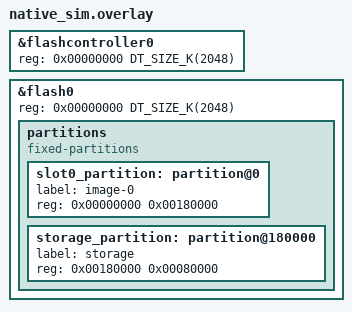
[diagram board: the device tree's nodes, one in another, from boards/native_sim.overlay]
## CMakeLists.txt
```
# SPDX-License-Identifier: GPL-3.0-or-later
#
# Method 4 (PAIRING_CA_ANCHOR) pairing gate conformance on native_sim (T-19).
#
# Drives pairing.c (CA_ANCHOR path) + ca.c + storage.c against a simulated
# LittleFS partition.  A session stub injects client cert chains; ca.c
# (provisioned with a real slot-0 CA) is used to sign test client certs.
#
# Build:
#   ZEPHYR_TOOLCHAIN_VARIANT=host \
#     west build -p -b native_sim firmware/tests/pairing_ca_anchor --no-sysbuild
#   west build -t run

cmake_minimum_required(VERSION 3.20.0)

find_package(Zephyr REQUIRED HINTS $ENV{ZEPHYR_BASE})
project(pairing_ca_anchor_tests LANGUAGES C)

set(FW ${CMAKE_CURRENT_SOURCE_DIR}/../..)

target_sources(app PRIVATE
    src/main.c
    src/session_stub.c
    ${FW}/src/clients/pairing.c
    ${FW}/src/ca/ca.c
    ${FW}/src/ca/der_write.c
    ${FW}/src/ca/certparse_wolfssl.c
    ${FW}/src/ca/certgen_wolfssl.c
    ${FW}/src/crypto/crypto_wolfssl.c
    ${FW}/src/crypto/wc_rand.c
    ${FW}/src/crypto/zeroize.c
    ${FW}/src/storage/storage.c
    ${FW}/src/storage/volume_marker.c
    ${FW}/src/crypto/device_id.c
    ${FW}/../common/cbor/cantil_cbor.c
)

target_include_directories(app PRIVATE
    ${FW}/src
    ${FW}/include
    ${FW}/../common/cbor
    ${FW}/tests/common
)

zephyr_include_directories(${FW}/include)

# Carries WOLFSSL_USER_SETTINGS / WOLFSSL_ZEPHYR defines.
target_link_libraries(app PRIVATE wolfSSL)
```

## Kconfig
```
# SPDX-License-Identifier: GPL-3.0-or-later

mainmenu "pairing_ca_anchor ztest"

config CANTIL_MAX_KEY_SLOTS
	int "Maximum number of key slots"
	default 8
	range 1 64

config CANTIL_CRL_VALIDITY_SEC
	int "CRL nextUpdate window (seconds)"
	default 86400

config CANTIL_REVOKE_REQUIRE_NOW_UNIX
	bool "Require host-supplied revocation timestamp"
	default n

# Pairing method symbols — flat booleans (no choice wrapper in test context).
config PAIRING_PROMISCUOUS
	bool "Method 0 — Promiscuous"
	default n

config PAIRING_TOFU
	bool "Method 1 — Silent TOFU"
	default n

config PAIRING_TAP_CONFIRM
	bool "Method 2 — Tap-confirmed bond"
	default n

config PAIRING_PASSKEY
	bool "Method 3 — Passkey + tap-confirmed bond"
	default n

config PAIRING_CA_ANCHOR
	bool "Method 4 — CA-anchored client cert"
	default n

config CANTIL_CA_ANCHOR_SLOT
	int "CA slot to use as trust anchor for Method 4"
	default 0
	depends on PAIRING_CA_ANCHOR

source "Kconfig.zephyr"
```

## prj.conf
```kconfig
# ztest framework
CONFIG_ZTEST=y

# Pairing method under test.
CONFIG_PAIRING_CA_ANCHOR=y
CONFIG_CANTIL_CA_ANCHOR_SLOT=0
CONFIG_CANTIL_MAX_KEY_SLOTS=8

# Entropy — native_sim has zephyr,native-posix-rng.
CONFIG_ENTROPY_GENERATOR=y
CONFIG_TEST_RANDOM_GENERATOR=y

# LittleFS on the sim flash partition.
CONFIG_FLASH=y
CONFIG_FLASH_MAP=y
CONFIG_FILE_SYSTEM=y
CONFIG_FILE_SYSTEM_LITTLEFS=y
CONFIG_FS_LITTLEFS_FMP_DEV=y
CONFIG_FILE_SYSTEM_MKFS=y

# wolfCrypt — full CA path (ECDSA P-256, AES-256-GCM, HKDF-SHA256) plus the
# X.509 writer and reader. Which primitives compile is decided by the settings
# header, not by Kconfig — see cantil_wolfssl_user_settings.h.
CONFIG_WOLFSSL=y
CONFIG_WOLFSSL_BUILTIN=y
CONFIG_WOLFSSL_SETTINGS_FILE="cantil_wolfssl_user_settings.h"

# Device-id source for the FICR-derived storage key.
CONFIG_HWINFO=y

CONFIG_MAIN_STACK_SIZE=16384
CONFIG_HEAP_MEM_POOL_SIZE=32768

# crc32_ieee — storage.c volume identity marker
CONFIG_CRC=y
```

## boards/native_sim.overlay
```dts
/* Same flash layout as sign_csr / session_slot tests — 512 KB storage partition. */

&flashcontroller0 {
	reg = <0x00000000 DT_SIZE_K(2048)>;
};

&flash0 {
	reg = <0x00000000 DT_SIZE_K(2048)>;
	partitions {
		compatible = "fixed-partitions";
		#address-cells = <1>;
		#size-cells = <1>;

		/delete-node/ partition@0;
		/delete-node/ partition@c000;
		/delete-node/ partition@75000;
		/delete-node/ partition@de000;
		/delete-node/ partition@fc000;

		slot0_partition: partition@0 {
			label = "image-0";
			reg = <0x00000000 0x00180000>;
		};
		storage_partition: partition@180000 {
			label = "storage";
			reg = <0x00180000 0x00080000>;
		};
	};
};
```

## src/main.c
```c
/* SPDX-License-Identifier: GPL-3.0-or-later */
/* See LICENSE at the repo root. */

/*
 * Method 4 (PAIRING_CA_ANCHOR) pairing gate conformance on native_sim (T-19).
 *
 * Drives pairing.c + ca.c + storage.c against a simulated flash partition.
 * Suite setup provisions slot 0 as a CA (the trust anchor) and generates a
 * test client cert signed by it.  Per-test setup resets the session stub.
 *
 * Coverage:
 *   1. Valid client cert (signed by slot 0) → 0 (session allowed, no bond).
 *   2. No client cert in msg3 (cert_count == 0) → -EACCES.
 *   3. Client cert self-signed (not by slot 0) → -EACCES.
 *   4. Slot 0 anchor not provisioned (cert.der deleted) → -EACCES.
 *   5. Corrupted cert DER (random bytes) → -EACCES.
 */

#include <zephyr/kernel.h>
#include <zephyr/ztest.h>
#include <zephyr/fs/fs.h>
#include <string.h>
#include <errno.h>

#include "ca/ca.h"
#include "test_pki.h"
#include "crypto/crypto.h"
#include "storage/storage.h"
#include "clients/pairing.h"
#include "session/session.h"

/* Declared in session_stub.c */
cantil_session_t *ca_anchor_test_session(void);
void ca_anchor_test_set_client_certs(const uint8_t *const ders[], const size_t lens[],
				     size_t count);
void ca_anchor_test_clear_client_certs(void);

/* ── Test-owned cert DER buffers (populated once in suite_setup) ─────────── */

static uint8_t g_anchor_cert_der[1024]; /* slot 0 CA cert — trust anchor */
static size_t g_anchor_cert_len;

static uint8_t g_valid_cert_der[1024]; /* client cert signed by slot 0 */
static size_t g_valid_cert_len;

static uint8_t g_self_signed_cert_der[1024]; /* cert with unknown CA */
static size_t g_self_signed_cert_len;

/* ── Helpers ─────────────────────────────────────────────────────────────── */

static void wipe_dir(const char *path)
{
	struct fs_dir_t dir;
	struct fs_dirent ent;
	char child[128];

	fs_dir_t_init(&dir);
	if (fs_opendir(&dir, path) != 0) {
		return;
	}
	while (fs_readdir(&dir, &ent) == 0 && ent.name[0] != '\0') {
		snprintf(child, sizeof(child), "%s/%s", path, ent.name);
		if (ent.type == FS_DIR_ENTRY_DIR) {
			wipe_dir(child);
		}
		fs_unlink(child);
	}
	fs_closedir(&dir);
	fs_unlink(path);
}

static size_t build_ca_x509_blob(uint8_t *out, size_t cap)
{
	size_t off = 0;
	const char *cn = "Cantil Test CA";
	const char *o = "Cantil";

	zassert_true(cap >= 64, "blob buffer too small");
	out[off++] = 0x01;
	out[off++] = 0x68; /* validity_days = 360 */
	out[off++] = 1;    /* is_ca */
	out[off++] = 0;    /* path_len = 0 */
	out[off++] = 0x00;
	out[off++] = 0x86; /* KU: digSig|keyCertSign|cRLSign */

	out[off++] = (uint8_t)strlen(cn);
	memcpy(&out[off], cn, strlen(cn));
	off += strlen(cn);
	out[off++] = (uint8_t)strlen(o);
	memcpy(&out[off], o, strlen(o));
	off += strlen(o);
	out[off++] = 0; /* ou */
	out[off++] = 0; /* c  */
	out[off++] = 0; /* st */
	out[off++] = 0; /* l  */
	return off;
}

/* A fresh client CSR (CN=TestClient), minted via the wolfCrypt writer. */
static int build_client_csr(uint8_t *csr_der, size_t *csr_len)
{
	return test_pki_csr_cn("TestClient", csr_der, csr_len, NULL);
}

/* A self-signed leaf under an unrelated key (CN=Unknown) — a cert that does
 * NOT chain to slot 0, which the trust-tier tests expect to be rejected. */
static int build_self_signed_cert(uint8_t *cert_der, size_t *cert_len)
{
	certgen_dn_t dn = test_pki_dn_cn("Unknown");

	return test_pki_self_signed(&dn, false, cert_der, cert_len, NULL);
}

/* ── Suite setup ─────────────────────────────────────────────────────────── */

static void *suite_setup(void)
{
	zassert_ok(storage_init(), "storage_init failed");

	/*
	 * A fresh native_sim volume has no identity marker, and minting is now
	 * refused on an unmarked, empty volume — that combination is what a
	 * misdeclared partition looks like. Mark it, which is exactly what the
	 * factory image does to real hardware before anything is provisioned.
	 */
	(void)storage_volume_marker_write();

	/* Provision slot 0 as trust anchor CA. */
	wipe_dir("/lfs/keys/0");
	zassert_ok(ca_provision(0), "ca_provision failed");

	uint8_t blob[64];
	size_t blob_len = build_ca_x509_blob(blob, sizeof(blob));

	zassert_ok(ca_push_key_x509(0, blob, blob_len), "ca_push_key_x509 failed");
	zassert_true(ca_ready(), "slot 0 not ready after push");

	/* Save the anchor cert for test 4's restore path. */
	g_anchor_cert_len = sizeof(g_anchor_cert_der);
	zassert_ok(storage_slot_cert_read(0, g_anchor_cert_der, &g_anchor_cert_len),
		   "could not read slot 0 cert after push");

	/* Sign a test client CSR with slot 0 → g_valid_cert_der. */
	uint8_t csr_buf[512];
	size_t csr_len = sizeof(csr_buf);

	zassert_ok(build_client_csr(csr_buf, &csr_len), "client CSR build failed");

	g_valid_cert_len = sizeof(g_valid_cert_der);
	zassert_ok(ca_sign_csr_slot(0, csr_buf, csr_len, g_valid_cert_der, &g_valid_cert_len),
		   "CA sign CSR failed");

	/* Build a self-signed cert not anchored in slot 0 → g_self_signed_cert_der. */
	g_self_signed_cert_len = sizeof(g_self_signed_cert_der);
	zassert_ok(build_self_signed_cert(g_self_signed_cert_der, &g_self_signed_cert_len),
		   "self-signed cert build failed");

	return NULL;
}

static void before(void *unused)
{
	ARG_UNUSED(unused);
	ca_anchor_test_clear_client_certs();
}

ZTEST_SUITE(pairing_ca_anchor, NULL, suite_setup, before, NULL, NULL);

static const uint8_t PUB_A[32] = {0xAA, 0x01, 0x02, 0x03};

/* ── Test 1: valid cert (signed by slot 0) → allowed ────────────────────── */

ZTEST(pairing_ca_anchor, test_valid_cert_allowed)
{
	const uint8_t *ders[1] = {g_valid_cert_der};
	size_t lens[1] = {g_valid_cert_len};

	ca_anchor_test_set_client_certs(ders, lens, 1);

	cantil_session_t *s = ca_anchor_test_session();

	zassert_ok(pairing_check_and_bond(PUB_A, s), "Method 4: valid cert should be allowed");
}

/* ── Test 2: no cert chain → rejected ───────────────────────────────────── */

ZTEST(pairing_ca_anchor, test_no_cert_rejected)
{
	cantil_session_t *s = ca_anchor_test_session();
	int rc = pairing_check_and_bond(PUB_A, s);

	zassert_equal(rc, -EACCES, "Method 4: no cert should be rejected, got %d", rc);
}

/* ── Test 3: self-signed cert (not from slot 0) → rejected ──────────────── */

ZTEST(pairing_ca_anchor, test_wrong_ca_rejected)
{
	const uint8_t *ders[1] = {g_self_signed_cert_der};
	size_t lens[1] = {g_self_signed_cert_len};

	ca_anchor_test_set_client_certs(ders, lens, 1);

	cantil_session_t *s = ca_anchor_test_session();
	int rc = pairing_check_and_bond(PUB_A, s);

	zassert_equal(rc, -EACCES, "Method 4: cert from wrong CA should be rejected, got %d", rc);
}

/* ── Test 4: slot 0 cert.der deleted (anchor missing) → rejected ─────────── */

ZTEST(pairing_ca_anchor, test_anchor_missing_rejected)
{
	/* Temporarily remove the anchor cert. */
	zassert_ok(fs_unlink("/lfs/keys/0/cert.der"), "could not delete anchor cert for test");

	const uint8_t *ders[1] = {g_valid_cert_der};
	size_t lens[1] = {g_valid_cert_len};

	ca_anchor_test_set_client_certs(ders, lens, 1);

	cantil_session_t *s = ca_anchor_test_session();
	int rc = pairing_check_and_bond(PUB_A, s);

	/* Restore the anchor cert so test 5 can still use it. */
	zassert_ok(storage_slot_cert_write(0, g_anchor_cert_der, g_anchor_cert_len),
		   "restore of anchor cert failed — test 5 may fail");

	zassert_equal(rc, -EACCES, "Method 4: missing anchor should reject, got %d", rc);
}

/* ── Test 5: corrupted cert DER → rejected ───────────────────────────────── */

ZTEST(pairing_ca_anchor, test_corrupted_cert_rejected)
{
	static const uint8_t junk[32] = {
		0xFF, 0xFE, 0xFD, 0xFC, 0xFB, 0xFA, 0xF9, 0xF8, 0xF7, 0xF6, 0xF5,
		0xF4, 0xF3, 0xF2, 0xF1, 0xF0, 0xEF, 0xEE, 0xED, 0xEC, 0xEB, 0xEA,
		0xE9, 0xE8, 0xE7, 0xE6, 0xE5, 0xE4, 0xE3, 0xE2, 0xE1, 0xE0,
	};
	const uint8_t *ders[1] = {junk};
	size_t lens[1] = {sizeof(junk)};

	ca_anchor_test_set_client_certs(ders, lens, 1);

	cantil_session_t *s = ca_anchor_test_session();
	int rc = pairing_check_and_bond(PUB_A, s);

	zassert_equal(rc, -EACCES, "Method 4: corrupted cert should be rejected, got %d", rc);
}
```

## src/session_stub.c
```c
/* SPDX-License-Identifier: GPL-3.0-or-later */
/* See LICENSE at the repo root. */

/*
 * Session stub for the pairing_ca_anchor ztest suite (T-19).
 *
 * pairing.c (PAIRING_CA_ANCHOR) calls:
 *   session_get_client_cert_count() — how many client certs the peer sent
 *   session_get_client_cert()       — borrow the Nth cert DER
 *
 * Test controls (called from main.c):
 *   ca_anchor_test_session()           — return the stub cantil_session_t
 *   ca_anchor_test_set_client_certs()  — inject cert chain for next call
 *   ca_anchor_test_clear_client_certs() — reset to "no cert" (cert_count == 0)
 */

#include <zephyr/kernel.h>
#include <string.h>
#include <errno.h>

#include "session/session.h"

#define MAX_TEST_CERTS 4

/* Minimal concrete struct — opaque in session.h. */
struct cantil_session {
	bool established;
	/* Injected client cert chain (borrowed pointers — not freed here). */
	const uint8_t *cert_ders[MAX_TEST_CERTS];
	size_t cert_lens[MAX_TEST_CERTS];
	size_t cert_count;
};

static struct cantil_session stub_session = {.established = true};

cantil_session_t *ca_anchor_test_session(void)
{
	return &stub_session;
}

void ca_anchor_test_set_client_certs(const uint8_t *const ders[], const size_t lens[], size_t count)
{
	stub_session.cert_count = (count > MAX_TEST_CERTS) ? MAX_TEST_CERTS : count;
	for (size_t i = 0; i < stub_session.cert_count; i++) {
		stub_session.cert_ders[i] = ders[i];
		stub_session.cert_lens[i] = lens[i];
	}
}

void ca_anchor_test_clear_client_certs(void)
{
	stub_session.cert_count = 0;
}

/* ── session API stubs ─────────────────────────────────────────────────── */

size_t session_get_client_cert_count(const cantil_session_t *s)
{
	return s ? s->cert_count : 0;
}

int session_get_client_cert(const cantil_session_t *s, size_t idx, const uint8_t **der, size_t *len)
{
	if (!s || !der || !len) {
		return -EINVAL;
	}
	if (idx >= s->cert_count) {
		return -ENOENT;
	}
	*der = s->cert_ders[idx];
	*len = s->cert_lens[idx];
	return 0;
}

/* Remaining session API is not called by pairing.c (PAIRING_CA_ANCHOR). */

int session_open(cantil_transport_t *t, const uint8_t *pub, cantil_session_t **out)
{
	ARG_UNUSED(t);
	ARG_UNUSED(pub);
	ARG_UNUSED(out);
	return -ENOSYS;
}

void session_close(cantil_session_t *s)
{
	ARG_UNUSED(s);
}

int session_send(cantil_session_t *s, const uint8_t *buf, size_t len)
{
	ARG_UNUSED(s);
	ARG_UNUSED(buf);
	ARG_UNUSED(len);
	return -ENOSYS;
}

int session_recv(cantil_session_t *s, uint8_t *buf, size_t max, size_t *got)
{
	ARG_UNUSED(s);
	ARG_UNUSED(buf);
	ARG_UNUSED(max);
	ARG_UNUSED(got);
	return -ENOSYS;
}

int session_get_remote_pubkey(cantil_session_t *s, uint8_t pub[32])
{
	ARG_UNUSED(s);
	ARG_UNUSED(pub);
	return -ENOSYS;
}

int session_get_local_pubkey(cantil_session_t *s, uint8_t pub[32])
{
	ARG_UNUSED(s);
	ARG_UNUSED(pub);
	return -ENOSYS;
}
```
